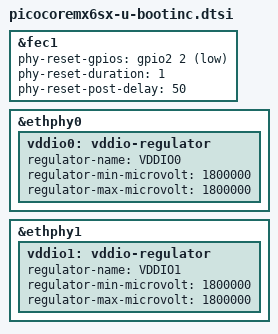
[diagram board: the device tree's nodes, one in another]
&fec1 {
	// MX6SX_PAD_ENET1_MDC__GPIO2_IO_2
	phy-reset-gpios = <&gpio2 2 GPIO_ACTIVE_LOW>;
	phy-reset-duration = <1>;
	phy-reset-post-delay = <50>;
};

&ethphy0 {
	//qca,clk-out-frequency = <125000000>;
	//qca,keep-pll-enabled;
	//qca,no-eee;

	vddio0: vddio-regulator {
		regulator-name = "VDDIO0";
		regulator-min-microvolt = <1800000>;
		regulator-max-microvolt = <1800000>;
	};
};

&ethphy1 {
	//qca,clk-out-frequency = <125000000>;
	//qca,keep-pll-enabled;
	//qca,no-eee;

	vddio1: vddio-regulator {
		regulator-name = "VDDIO1";
		regulator-min-microvolt = <1800000>;
		regulator-max-microvolt = <1800000>;
	};
};
